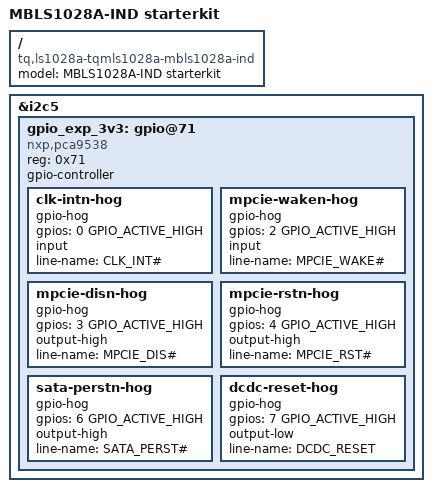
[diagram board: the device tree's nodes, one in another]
// SPDX-License-Identifier: (GPL-2.0-or-later OR MIT)
/*
 * Copyright 2019-2025 TQ-Systems GmbH <linux@ew.tq-group.com>,
 * D-82229 Seefeld, Germany.
 * Author: Michael Krummsdorf
 * Author: Matthias Schiffer
 * Author: Alexander Stein
 */

/dts-v1/;

#include "fsl-ls1028a-tqmls1028a-mbls1028a.dtsi"

/ {
	model = "MBLS1028A-IND starterkit";
	compatible = "tq,ls1028a-tqmls1028a-mbls1028a-ind", "tq,ls1028a-tqmls1028a", "fsl,ls1028a";
};

&i2c5 {
	gpio_exp_3v3: gpio@71 {
		compatible = "nxp,pca9538";
		reg = <0x71>;
		#gpio-cells = <2>;
		gpio-controller;

		clk-intn-hog {
			gpio-hog;
			gpios = <0 GPIO_ACTIVE_HIGH>;
			input;
			line-name = "CLK_INT#";
		};

		mpcie-waken-hog {
			gpio-hog;
			gpios = <2 GPIO_ACTIVE_HIGH>;
			input;
			line-name = "MPCIE_WAKE#";
		};

		mpcie-disn-hog {
			gpio-hog;
			gpios = <3 GPIO_ACTIVE_HIGH>;
			output-high;
			line-name = "MPCIE_DIS#";
		};

		mpcie-rstn-hog {
			gpio-hog;
			gpios = <4 GPIO_ACTIVE_HIGH>;
			output-high;
			line-name = "MPCIE_RST#";
		};

		sata-perstn-hog {
			gpio-hog;
			gpios = <6 GPIO_ACTIVE_HIGH>;
			output-high;
			line-name = "SATA_PERST#";
		};

		dcdc-reset-hog {
			gpio-hog;
			gpios = <7 GPIO_ACTIVE_HIGH>;
			output-low;
			line-name = "DCDC_RESET";
		};
	};
};
